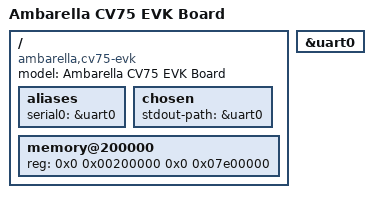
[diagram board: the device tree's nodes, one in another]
// SPDX-License-Identifier: GPL-2.0-or-later
/*
 * Ambarella CV75 EVK board
 */

/dts-v1/;

#include "cv75.dtsi"

/ {
	model = "Ambarella CV75 EVK Board";
	compatible = "ambarella,cv75-evk", "ambarella,cv75";

	aliases {
		serial0 = &uart0;
	};

	chosen {
		stdout-path = &uart0;
	};

	memory@200000 {
		device_type = "memory";
		reg = <0x0 0x00200000 0x0 0x07e00000>;
	};
};

&uart0 {
	status = "okay";
};
